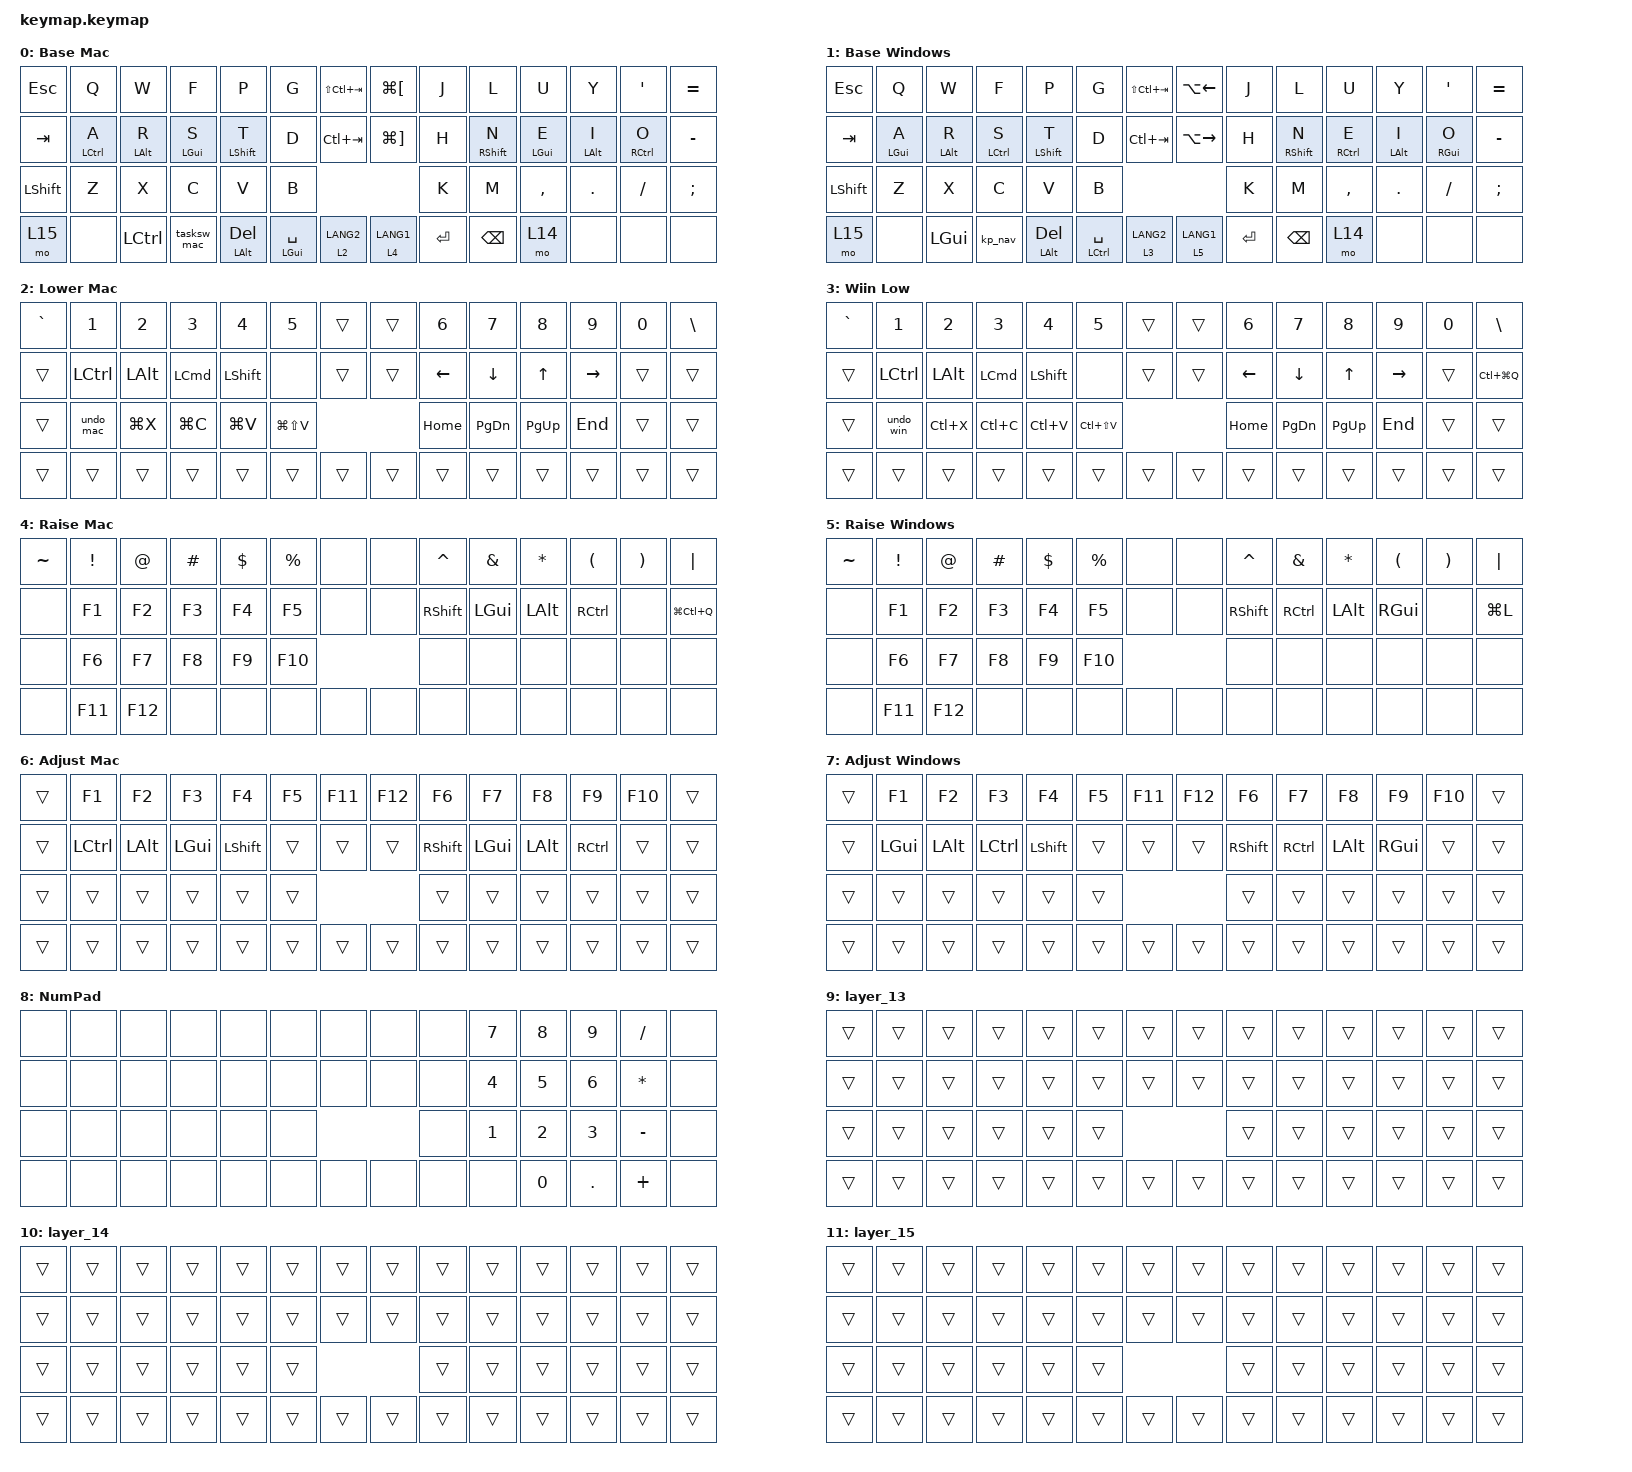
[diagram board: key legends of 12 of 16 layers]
#include "zmk-helpers/helper.h"

#define ZMK_POINTING_DEFAULT_MOVE_VAL 600  // default: 600
#define ZMK_POINTING_DEFAULT_SCRL_VAL 10    // default: 10

#include <dt-bindings/zmk/mouse.h>
#include <behaviors.dtsi>
#include <dt-bindings/zmk/bt.h>
#include <dt-bindings/zmk/keys.h>
#include <dt-bindings/zmk/outputs.h>
#include <dt-bindings/zmk/pointing.h>

#define MBASE 0
#define WBASE 1
#define MLOWER 2
#define WLOWER 3
#define MRAISE 4
#define WRAISE 5
#define MADJUST 6
#define WADJUST 7
#define DEVICE 8
#define MODE 10

&mt { tapping-term-ms = <180>; };

&lt { tapping-term-ms = <180>; };

&sl { release-after-ms = <2000>; };

/ {
    behaviors {
        hml: home_row_mod_left {
            compatible = "zmk,behavior-hold-tap";
            #binding-cells = <2>;
            flavor = "balanced";
            tapping-term-ms = <280>;
            require-prior-idle-ms = <150>;
            quick-tap-ms = <175>;
            hold-trigger-key-positions = <
                7  8  9 10 11 12 13
                21 22 23 24 25 26 27
                34 35 36 37 38 39
                47 48 49 50 51 52 53
            >;

            hold-trigger-on-release;
            bindings = <&kp>, <&kp>;
        };

        hmr: home_row_mod_right {
            compatible = "zmk,behavior-hold-tap";
            #binding-cells = <2>;
            flavor = "balanced";
            tapping-term-ms = <280>;
            require-prior-idle-ms = <150>;
            quick-tap-ms = <175>;
            hold-trigger-key-positions = <
                0  1  2  3  4  5  6
                14 15 16 17 18 19 20
                28 29 30 31 32 33
                40 41 42 43 44 45 46
            >;

            hold-trigger-on-release;
            bindings = <&kp>, <&kp>;
        };

        pst_mac: paste_mac {
            compatible = "zmk,behavior-tap-dance";
            #binding-cells = <0>;
            tapping-term-ms = <180>;
            bindings = <&kp LG(V)>, <&kp LS(LG(V))>;
        };

        pst_win: paste_win {
            compatible = "zmk,behavior-tap-dance";
            #binding-cells = <0>;
            tapping-term-ms = <180>;
            bindings = <&kp LC(V)>, <&kp LS(LC(V))>;
        };

        undo_mac: undo_mac {
            compatible = "zmk,behavior-tap-dance";
            #binding-cells = <0>;
            tapping-term-ms = <180>;
            bindings = <&kp LG(Z)>, <&kp LS(LG(Z))>;
        };

        undo_win: undo_win {
            compatible = "zmk,behavior-tap-dance";
            #binding-cells = <0>;
            tapping-term-ms = <180>;
            bindings = <&kp LC(Z)>, <&kp LS(LC(Z))>;
        };

        tasksw_mac: tasksw_mac {
            compatible = "zmk,behavior-tap-dance";
            label = "TASKSW_MAC";
            #binding-cells = <0>;
            bindings = <&lt 8 LG(SPACE)>, <&lt 13 LA(SPACE)>, <&none>;

            tapping-term-ms = <180>;
        };

        tog_off: tog_off {
            compatible = "zmk,behavior-toggle-layer";
            label = "TOG_OFF";
            #binding-cells = <1>;
            toggle-mode = "off";
        };

        tog_on: tog_on {
            compatible = "zmk,behavior-toggle-layer";
            label = "TOG_ON";
            #binding-cells = <1>;
        };

        kp_nav: kp_nav {
            compatible = "zmk,behavior-tap-dance";
            label = "KP_NAV";
            #binding-cells = <0>;
            bindings = <&mo 8>, <&mo 13>;

            tapping-term-ms = <180>;
        };
    };

    conditional_layers {
        compatible = "zmk,conditional-layers";

        tri_layer_mac {
            if-layers = <2 4>;
            then-layer = <6>;
        };

        tri_layer_win {
            if-layers = <5 3>;
            then-layer = <7>;
        };
    };

    keymap {
        compatible = "zmk,keymap";

        base-m {
            display-name = "Base Mac";
            bindings = <
&kp ESC    &kp Q         &kp W        &kp F        &kp P         &kp G           &kp LS(LC(TAB))  &kp LG(LBKT)  &kp J    &kp L         &kp U        &kp Y        &kp SQT       &kp EQUAL
&kp TAB    &hml LCTRL A  &hml LALT R  &hml LGUI S  &hml LSHFT T  &kp D           &kp LC(TAB)      &kp LG(RBKT)  &kp H    &hmr RSHFT N  &hmr LGUI E  &hmr LALT I  &hmr RCTRL O  &kp MINUS
&kp LSHFT  &kp Z         &kp X        &kp C        &kp V         &kp B                                          &kp K    &kp M         &kp COMMA    &kp DOT      &kp SLASH     &kp SEMI
&mo 15     &none         &kp LCTRL    &tasksw_mac  &mt LALT DEL  &mt LGUI SPACE  &lt 2 LANG2      &lt 4 LANG1   &kp RET  &kp BSPC      &mo 14       &none        &none         &none
            >;

            label = "M Base";
        };

        base-w {
            display-name = "Base Windows";
            bindings = <
&kp ESC    &kp Q        &kp W        &kp F         &kp P         &kp G            &kp LS(LC(TAB))  &kp LA(LEFT)   &kp J    &kp L         &kp U         &kp Y        &kp SQT      &kp EQUAL
&kp TAB    &hml LGUI A  &hml LALT R  &hml LCTRL S  &hml LSHFT T  &kp D            &kp LC(TAB)      &kp LA(RIGHT)  &kp H    &hmr RSHFT N  &hmr RCTRL E  &hmr LALT I  &hmr RGUI O  &kp MINUS
&kp LSHFT  &kp Z        &kp X        &kp C         &kp V         &kp B                                            &kp K    &kp M         &kp COMMA     &kp DOT      &kp SLASH    &kp SEMI
&mo 15     &none        &kp LGUI     &kp_nav       &mt LALT DEL  &mt LCTRL SPACE  &lt 3 LANG2      &lt 5 LANG1    &kp RET  &kp BSPC      &mo 14        &none        &none        &none
            >;

            label = "W Base";
        };

        lower-m {
            display-name = "Lower Mac";
            bindings = <
&kp GRAVE  &kp N1     &kp N2     &kp N3     &kp N4      &kp N5         &trans  &trans  &kp N6    &kp N7     &kp N8     &kp N9     &kp N0  &kp BSLH
&trans     &kp LCTRL  &kp LALT   &kp LCMD   &kp LSHIFT  &none          &trans  &trans  &kp LEFT  &kp DOWN   &kp UP     &kp RIGHT  &trans  &trans
&trans     &undo_mac  &kp LG(X)  &kp LG(C)  &kp LG(V)   &kp LG(LS(V))                  &kp HOME  &kp PG_DN  &kp PG_UP  &kp END    &trans  &trans
&trans     &trans     &trans     &trans     &trans      &trans         &trans  &trans  &trans    &trans     &trans     &trans     &trans  &trans
            >;

            label = "M  LWR";
        };

        lower-w {
            display-name = "Wiin Low";
            bindings = <
&kp GRAVE  &kp N1     &kp N2     &kp N3     &kp N4      &kp N5         &trans  &trans  &kp N6    &kp N7     &kp N8     &kp N9     &kp N0  &kp BSLH
&trans     &kp LCTRL  &kp LALT   &kp LCMD   &kp LSHIFT  &none          &trans  &trans  &kp LEFT  &kp DOWN   &kp UP     &kp RIGHT  &trans  &kp LC(LG(Q))
&trans     &undo_win  &kp LC(X)  &kp LC(C)  &kp LC(V)   &kp LC(LS(V))                  &kp HOME  &kp PG_DN  &kp PG_UP  &kp END    &trans  &trans
&trans     &trans     &trans     &trans     &trans      &trans         &trans  &trans  &trans    &trans     &trans     &trans     &trans  &trans
            >;

            label = "W  LWR";
        };

        raise-m {
            display-name = "Raise Mac";
            bindings = <
&kp TILDE  &kp EXCL  &kp AT   &kp HASH  &kp DLLR  &kp PRCNT  &none  &none  &kp CARET  &kp AMPS  &kp STAR  &kp LPAR   &kp RPAR  &kp PIPE
&none      &kp F1    &kp F2   &kp F3    &kp F4    &kp F5     &none  &none  &kp RSHFT  &kp LGUI  &kp LALT  &kp RCTRL  &none     &kp LG(LC(Q))
&none      &kp F6    &kp F7   &kp F8    &kp F9    &kp F10                  &none      &none     &none     &none      &none     &none
&none      &kp F11   &kp F12  &none     &none     &none      &none  &none  &none      &none     &none     &none      &none     &none
            >;

            label = "M RSE";
        };

        raise-w {
            label = "W  RSE";
            display-name = "Raise Windows";
            bindings = <
&kp TILDE  &kp EXCL  &kp AT   &kp HASH  &kp DLLR  &kp PRCNT  &none  &none  &kp CARET  &kp AMPS   &kp STAR  &kp LPAR  &kp RPAR  &kp PIPE
&none      &kp F1    &kp F2   &kp F3    &kp F4    &kp F5     &none  &none  &kp RSHFT  &kp RCTRL  &kp LALT  &kp RGUI  &none     &kp LG(L)
&none      &kp F6    &kp F7   &kp F8    &kp F9    &kp F10                  &none      &none      &none     &none     &none     &none
&none      &kp F11   &kp F12  &none     &none     &none      &none  &none  &none      &none      &none     &none     &none     &none
            >;
        };

        adjust-m {
            display-name = "Adjust Mac";
            bindings = <
&trans  &kp F1     &kp F2    &kp F3    &kp F4     &kp F5  &kp F11  &kp F12  &kp F6     &kp F7    &kp F8    &kp F9     &kp F10  &trans
&trans  &kp LCTRL  &kp LALT  &kp LGUI  &kp LSHFT  &trans  &trans   &trans   &kp RSHFT  &kp LGUI  &kp LALT  &kp RCTRL  &trans   &trans
&trans  &trans     &trans    &trans    &trans     &trans                    &trans     &trans    &trans    &trans     &trans   &trans
&trans  &trans     &trans    &trans    &trans     &trans  &trans   &trans   &trans     &trans    &trans    &trans     &trans   &trans
            >;

            label = "M  ADJ";
        };

        adjust-w {
            label = "W  ADJ";
            display-name = "Adjust Windows";
            bindings = <
&trans  &kp F1    &kp F2    &kp F3     &kp F4     &kp F5  &kp F11  &kp F12  &kp F6     &kp F7     &kp F8    &kp F9    &kp F10  &trans
&trans  &kp LGUI  &kp LALT  &kp LCTRL  &kp LSHFT  &trans  &trans   &trans   &kp RSHFT  &kp RCTRL  &kp LALT  &kp RGUI  &trans   &trans
&trans  &trans    &trans    &trans     &trans     &trans                    &trans     &trans     &trans    &trans    &trans   &trans
&trans  &trans    &trans    &trans     &trans     &trans  &trans   &trans   &trans     &trans     &trans    &trans    &trans   &trans
            >;
        };

        kp {
            bindings = <
&none  &none  &none  &none  &none  &none  &none  &none  &none  &kp N7  &kp N8  &kp N9   &kp SLASH  &none
&none  &none  &none  &none  &none  &none  &none  &none  &none  &kp N4  &kp N5  &kp N6   &kp STAR   &none
&none  &none  &none  &none  &none  &none                &none  &kp N1  &kp N2  &kp N3   &kp MINUS  &none
&none  &none  &none  &none  &none  &none  &none  &none  &none  &none   &kp N0  &kp DOT  &kp PLUS   &none
            >;

            label = "NumPad";
        };

        layer_13 {
            bindings = <
&trans  &trans  &trans  &trans  &trans  &trans  &trans  &trans  &trans  &trans  &trans  &trans  &trans  &trans
&trans  &trans  &trans  &trans  &trans  &trans  &trans  &trans  &trans  &trans  &trans  &trans  &trans  &trans
&trans  &trans  &trans  &trans  &trans  &trans                  &trans  &trans  &trans  &trans  &trans  &trans
&trans  &trans  &trans  &trans  &trans  &trans  &trans  &trans  &trans  &trans  &trans  &trans  &trans  &trans
            >;
        };

        layer_14 {
            bindings = <
&trans  &trans  &trans  &trans  &trans  &trans  &trans  &trans  &trans  &trans  &trans  &trans  &trans  &trans
&trans  &trans  &trans  &trans  &trans  &trans  &trans  &trans  &trans  &trans  &trans  &trans  &trans  &trans
&trans  &trans  &trans  &trans  &trans  &trans                  &trans  &trans  &trans  &trans  &trans  &trans
&trans  &trans  &trans  &trans  &trans  &trans  &trans  &trans  &trans  &trans  &trans  &trans  &trans  &trans
            >;
        };

        layer_15 {
            bindings = <
&trans  &trans  &trans  &trans  &trans  &trans  &trans  &trans  &trans  &trans  &trans  &trans  &trans  &trans
&trans  &trans  &trans  &trans  &trans  &trans  &trans  &trans  &trans  &trans  &trans  &trans  &trans  &trans
&trans  &trans  &trans  &trans  &trans  &trans                  &trans  &trans  &trans  &trans  &trans  &trans
&trans  &trans  &trans  &trans  &trans  &trans  &trans  &trans  &trans  &trans  &trans  &trans  &trans  &trans
            >;
        };

        novel {
            bindings = <
&tog_off 12  &kp F1  &kp F2  &kp F3  &kp F4     &kp F5     &trans  &trans   &kp F6     &kp F7     &kp F8     &kp F9     &kp F10  &kp F11
&trans       &trans  &trans  &trans  &trans     &trans     &trans  &trans   &kp LEFT   &kp DOWN   &kp UP     &kp RIGHT  &trans   &kp F12
&trans       &trans  &trans  &trans  &trans     &trans                      &kp HOME   &kp PG_DN  &kp PG_UP  &kp END    &trans   &trans
&trans       &trans  &trans  &trans  &kp LCTRL  &kp SPACE  &trans  &kp ESC  &kp ENTER  &kp BSPC   &trans     &trans     &trans   &trans
            >;

            label = "NovelG";
        };

        nav {
            display-name = "Navigation";
            bindings = <
&tog_off 13  &none  &none           &mmv MOVE_UP    &none            &none  &none  &none  &none     &none      &none      &none      &none  &none
&none        &none  &mmv MOVE_LEFT  &mmv MOVE_DOWN  &mmv MOVE_RIGHT  &none  &none  &none  &mkp MB4  &mkp LCLK  &mkp MCLK  &mkp RCLK  &none  &none
&none        &none  &none           &none           &none            &none                &mkp MB5  &none      &none      &none      &none  &none
&none        &none  &none           &none           &none            &none  &none  &none  &none     &none      &none      &none      &none  &none
            >;

            label = "NAV";
        };

        device {
            display-name = "Device";
            bindings = <
&none  &kp C_BRI_DN  &kp C_BRI_UP  &none  &none  &none  &none  &none  &kp C_PREV    &kp C_PP       &kp C_NEXT     &kp C_MUTE     &kp C_VOL_DN   &kp C_VOL_UP
&none  &none         &none         &none  &none  &none  &none  &none  &bt BT_CLR    &bt BT_DISC 0  &bt BT_DISC 1  &bt BT_DISC 2  &bt BT_DISC 3  &bt BT_DISC 4
&none  &none         &none         &none  &none  &none                &out OUT_TOG  &bt BT_SEL 0   &bt BT_SEL 1   &bt BT_SEL 2   &bt BT_SEL 3   &bt BT_SEL 4
&none  &none         &none         &none  &none  &none  &none  &none  &none         &none          &none          &none          &none          &none
            >;
        };

        mode {
            display-name = "MODE";
            bindings = <
&none   &none  &tog_on 1   &none  &none  &none       &none  &none  &none       &none       &none  &none  &none  &bootloader
&none   &none  &sys_reset  &none  &none  &tog_on 12  &none  &none  &tog_off 1  &tog_on 13  &none  &none  &none  &none
&none   &none  &none       &none  &none  &none                     &none       &none       &none  &none  &none  &none
&trans  &none  &none       &none  &none  &none       &none  &none  &none       &none       &none  &none  &none  &none
            >;
        };
    };
};
